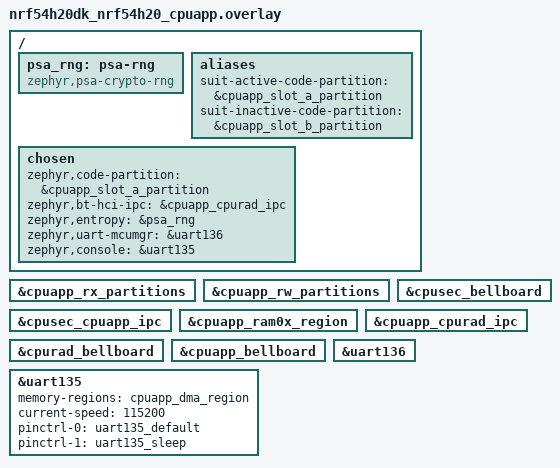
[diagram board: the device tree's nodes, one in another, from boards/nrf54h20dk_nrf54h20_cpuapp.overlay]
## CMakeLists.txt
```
#
# Copyright (c) 2025 Nordic Semiconductor ASA
#
# SPDX-License-Identifier: LicenseRef-Nordic-5-Clause
#

cmake_minimum_required(VERSION 3.13.1)

find_package(Zephyr REQUIRED HINTS $ENV{ZEPHYR_BASE})

project(suit_ab_images)

target_sources(app PRIVATE src/main.c)

# This project uses orginal sdk-zephyr C source code
target_include_directories(app PRIVATE $ENV{ZEPHYR_BASE}/samples/subsys/mgmt/mcumgr/smp_svr/src)
target_sources_ifdef(CONFIG_MCUMGR_TRANSPORT_BT app PRIVATE $ENV{ZEPHYR_BASE}/samples/subsys/mgmt/mcumgr/smp_svr/src/bluetooth.c)
```

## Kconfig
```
#
# Copyright (c) 2025 Nordic Semiconductor ASA
#
# SPDX-License-Identifier: LicenseRef-Nordic-5-Clause
#

config N_BLINKS
	int "Number of fast blinks"
	default 1

config ID_VAR_BOOT_STATUS
	int "Id of Manfiest-controlled variable representing a boot status"
	default 256

config ID_VAR_BOOT_PREFERENCE
	int "Id of Manfiest-controlled variable representing a boot prefrence"
	default 0

config ID_VAR_SET_TO_UPDATE
	int "Id of Manfiest-controlled variable representing image set to be updated"
	default 1

config ID_VAR_CONFIRM_SET_A
	int "Id of Manfiest-controlled variable representing after-update confirmation state for image set A"
	default 2

config ID_VAR_CONFIRM_SET_B
	int "Id of Manfiest-controlled variable representing after-update confirmation state for image set B"
	default 3

source "Kconfig.zephyr"
```

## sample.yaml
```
#
# Copyright (c) 2025 Nordic Semiconductor ASA
#
# SPDX-License-Identifier: LicenseRef-Nordic-5-Clause
#

sample:
  name: SUIT A/B update through SMP sample
  description: Sample application that A/B updates firmware using SUIT and SMP protocol
common:
  platform_allow: nrf54h20dk/nrf54h20/cpuapp
  build_only: true
  sysbuild: true
tests:
  sample.suit.ab:
    extra_args:
    - SB_EXTRA_CONF_FILE="suit_mpi.conf"
    tags:
      - suit
      - bluetooth
      - ci_samples_suit
```

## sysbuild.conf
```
#
# Copyright (c) 2025 Nordic Semiconductor ASA
#
# SPDX-License-Identifier: LicenseRef-Nordic-5-Clause
#

SB_CONFIG_SUIT_ENVELOPE=y
SB_CONFIG_NETCORE_HCI_IPC=y

SB_CONFIG_SUIT_BUILD_AB_UPDATE=y
SB_CONFIG_SUIT_MPI_APP_LOCAL_2=y
SB_CONFIG_SUIT_MPI_RAD_LOCAL_2=y
```

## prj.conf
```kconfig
#
# Copyright (c) 2025 Nordic Semiconductor ASA
#
# SPDX-License-Identifier: LicenseRef-Nordic-5-Clause
#

# Enable DK LED library
CONFIG_DK_LIBRARY=y

# Enable mcumgr
CONFIG_NET_BUF=y
CONFIG_ZCBOR=y
CONFIG_ZCBOR_CANONICAL=y
CONFIG_MCUMGR=y
CONFIG_MCUMGR_SMP_LEGACY_RC_BEHAVIOUR=y
CONFIG_CRC=y

# Enable SUIT services
CONFIG_SUIT=y
CONFIG_SUIT_DFU_CANDIDATE_PROCESSING_FULL=y
CONFIG_MGMT_SUITFU=y
CONFIG_FLASH=y

# Extended SUIT commands over USER group
CONFIG_MGMT_SUITFU_GRP_SUIT=y

# Enable bootloader identification within OS Management group
CONFIG_MCUMGR_GRP_OS=y
CONFIG_MCUMGR_GRP_OS_BOOTLOADER_INFO=y
CONFIG_MCUMGR_MGMT_NOTIFICATION_HOOKS=y
CONFIG_MCUMGR_GRP_OS_BOOTLOADER_INFO_HOOK=y

CONFIG_BT=y
CONFIG_BT_PERIPHERAL=y

# Optimize buffer sizes for transport speed
#CONFIG_MCUMGR_TRANSPORT_NETBUF_SIZE=1040
#CONFIG_UART_MCUMGR_RX_BUF_SIZE=1040
#CONFIG_MCUMGR_TRANSPORT_UART_MTU=1024

# Allow for large Bluetooth data packets.
CONFIG_BT_L2CAP_TX_MTU=498
CONFIG_BT_BUF_ACL_RX_SIZE=502
CONFIG_BT_BUF_ACL_TX_SIZE=502

# Enable the Bluetooth mcumgr transport (unauthenticated).
CONFIG_MCUMGR_TRANSPORT_BT=y
CONFIG_MCUMGR_TRANSPORT_BT_PERM_RW=y
CONFIG_MCUMGR_TRANSPORT_BT_CONN_PARAM_CONTROL=y

# Enable logs over UART
CONFIG_LOG=y
CONFIG_SUIT_LOG_LEVEL_DBG=y

# Enable the mcumgr Packet Reassembly feature over Bluetooth and its configuration dependencies.
# MCUmgr buffer size is optimized to fit one SMP packet divided into five Bluetooth Write Commands,
# transmitted with the maximum possible MTU value: 498 bytes.
CONFIG_MCUMGR_TRANSPORT_BT_REASSEMBLY=y
CONFIG_MCUMGR_TRANSPORT_NETBUF_SIZE=2475
CONFIG_MCUMGR_TRANSPORT_WORKQUEUE_STACK_SIZE=4096

CONFIG_BT_DEVICE_NAME="SUIT AB Sample"
```

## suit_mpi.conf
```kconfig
#
# Copyright (c) 2025 Nordic Semiconductor ASA
#
# SPDX-License-Identifier: LicenseRef-Nordic-5-Clause
#
# ATTENTION! This is the right place to define a configuration for SUIT manifests in end-product
# and practically all config values included in that file shall be adjusted according 
# to end-product needs/requirements.
# see: nrf/doc/nrf/app_dev/device_guides/nrf54h/ug_nrf54h20_suit_dfu.rst
# 
# SB_CONFIG_SUIT_MPI_$(manifest)_VENDOR_NAME: Vendor-specific string *SHALL* be configured for *ALL* listed entries below.
# It may be the same value, i.e. "acme.com", for all entries, replacing existing "nordicsemi.com"
#
# SB_CONFIG_SUIT_MPI_$(manifest)_CLASS_NAME: Unique string prevents an update with firmware dedicated to other product
# Proposed schema: Manifest role + End Product model name.
# It *SHALL* be configured for *ALL* entries below, i.e.
# "nRF54H20_sample_root" replaced with "root_light_bulb_model_x123"
# "nRF54H20_sample_app" replaced with "app_A_light_bulb_model_x123"
# "nRF54H20_sample_app_local_2" replaced with "app_B_light_bulb_model_x123"
# 
# Signature check policy for given manifest, select one of possible options:
# SB_CONFIG_SUIT_MPI_$(manifest)_SIGNATURE_CHECK_DISABLED=y, or
# SB_CONFIG_SUIT_MPI_$(manifest)_SIGNATURE_CHECK_ENABLED_ON_UPDATE=y, or
# SB_CONFIG_SUIT_MPI_$(manifest)_SIGNATURE_CHECK_ENABLED_ON_UPDATE_AND_BOOT=y

SB_CONFIG_SUIT_MPI_ROOT_VENDOR_NAME="nordicsemi.com"
SB_CONFIG_SUIT_MPI_ROOT_CLASS_NAME="nRF54H20_sample_root"
SB_CONFIG_SUIT_MPI_ROOT_DOWNGRADE_PREVENTION=y
SB_CONFIG_SUIT_MPI_ROOT_INDEPENDENT_UPDATE=y
SB_CONFIG_SUIT_MPI_ROOT_SIGNATURE_CHECK_ENABLED_ON_UPDATE_AND_BOOT=y

SB_CONFIG_SUIT_MPI_APP_RECOVERY=y
SB_CONFIG_SUIT_MPI_APP_RECOVERY_VENDOR_NAME="nordicsemi.com"
SB_CONFIG_SUIT_MPI_APP_RECOVERY_CLASS_NAME="nRF54H20_app_recovery"
SB_CONFIG_SUIT_MPI_APP_RECOVERY_DOWNGRADE_PREVENTION=y
SB_CONFIG_SUIT_MPI_APP_RECOVERY_INDEPENDENT_UPDATE=y
SB_CONFIG_SUIT_MPI_APP_RECOVERY_SIGNATURE_CHECK_ENABLED_ON_UPDATE_AND_BOOT=y

SB_CONFIG_SUIT_MPI_APP_LOCAL_1=y
SB_CONFIG_SUIT_MPI_APP_LOCAL_1_VENDOR_NAME="nordicsemi.com"
SB_CONFIG_SUIT_MPI_APP_LOCAL_1_CLASS_NAME="nRF54H20_sample_app"
SB_CONFIG_SUIT_MPI_APP_LOCAL_1_DOWNGRADE_PREVENTION=n
SB_CONFIG_SUIT_MPI_APP_LOCAL_1_INDEPENDENT_UPDATE=n
SB_CONFIG_SUIT_MPI_APP_LOCAL_1_SIGNATURE_CHECK_ENABLED_ON_UPDATE_AND_BOOT=y

SB_CONFIG_SUIT_MPI_APP_LOCAL_2=y
SB_CONFIG_SUIT_MPI_APP_LOCAL_2_VENDOR_NAME="nordicsemi.com"
SB_CONFIG_SUIT_MPI_APP_LOCAL_2_CLASS_NAME="nRF54H20_sample_app_local_2"
SB_CONFIG_SUIT_MPI_APP_LOCAL_2_DOWNGRADE_PREVENTION=n
SB_CONFIG_SUIT_MPI_APP_LOCAL_2_INDEPENDENT_UPDATE=n
SB_CONFIG_SUIT_MPI_APP_LOCAL_2_SIGNATURE_CHECK_ENABLED_ON_UPDATE_AND_BOOT=y

SB_CONFIG_SUIT_MPI_APP_LOCAL_3=n

SB_CONFIG_SUIT_MPI_RAD_RECOVERY=n

SB_CONFIG_SUIT_MPI_RAD_LOCAL_1=y
SB_CONFIG_SUIT_MPI_RAD_LOCAL_1_VENDOR_NAME="nordicsemi.com"
SB_CONFIG_SUIT_MPI_RAD_LOCAL_1_CLASS_NAME="nRF54H20_sample_rad"
SB_CONFIG_SUIT_MPI_RAD_LOCAL_1_DOWNGRADE_PREVENTION=n
SB_CONFIG_SUIT_MPI_RAD_LOCAL_1_INDEPENDENT_UPDATE=n
SB_CONFIG_SUIT_MPI_RAD_LOCAL_1_SIGNATURE_CHECK_ENABLED_ON_UPDATE_AND_BOOT=y

SB_CONFIG_SUIT_MPI_RAD_LOCAL_2=y
SB_CONFIG_SUIT_MPI_RAD_LOCAL_2_VENDOR_NAME="nordicsemi.com"
SB_CONFIG_SUIT_MPI_RAD_LOCAL_2_CLASS_NAME="nRF54H20_sample_rad_local_2"
SB_CONFIG_SUIT_MPI_RAD_LOCAL_2_DOWNGRADE_PREVENTION=n
SB_CONFIG_SUIT_MPI_RAD_LOCAL_2_INDEPENDENT_UPDATE=n
SB_CONFIG_SUIT_MPI_RAD_LOCAL_2_SIGNATURE_CHECK_ENABLED_ON_UPDATE_AND_BOOT=y
```

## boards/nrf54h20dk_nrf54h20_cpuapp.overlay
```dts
/*
 * Copyright (c) 2025 Nordic Semiconductor ASA
 *
 * SPDX-License-Identifier: LicenseRef-Nordic-5-Clause
 */

 #include "../sysbuild/nrf54h20dk_nrf54h20_memory_map.dtsi"

/* Enable partitions, belonging to the application domain. */
&cpuapp_rx_partitions {
	status = "okay";
};

&cpuapp_rw_partitions {
	status = "okay";
};

/* Enable IPC: Application <-> Secure */
&cpusec_cpuapp_ipc {
	status = "okay";
};

&cpuapp_ram0x_region {
	status = "okay";
};

&cpusec_bellboard {
	status = "okay";
};

/* Enable IPC: Application <-> Radio */
&cpuapp_cpurad_ipc {
	status = "okay";
};

&cpurad_bellboard {
	status = "okay";
};

&cpuapp_bellboard {
	status = "okay";
};

/* Disable HW flow control on the UART 0 */
&uart136 {
	/delete-property/ hw-flow-control;
};

/ {
	psa_rng: psa-rng {
		compatible = "zephyr,psa-crypto-rng";
		status = "okay";
	};

	aliases {
		suit-active-code-partition = &cpuapp_slot_a_partition;
		suit-inactive-code-partition = &cpuapp_slot_b_partition;
	};

	chosen {
		zephyr,code-partition = &cpuapp_slot_a_partition;
		zephyr,bt-hci-ipc = &cpuapp_cpurad_ipc;
		zephyr,entropy = &psa_rng;
		zephyr,uart-mcumgr = &uart136;
	};
};

/* UART 1 is configured for App Core console output. In order to use it for other
 * purpose, i.e. to output logs form the Radio core, remove section below.
 */
&uart135 {
	status = "okay";
	memory-regions = <&cpuapp_dma_region>;
	current-speed = <115200>;
	pinctrl-0 = <&uart135_default>;
	pinctrl-1 = <&uart135_sleep>;
	pinctrl-names = "default", "sleep";

	/delete-property/ hw-flow-control;
};

/ {
	chosen {
		zephyr,console = &uart135;
	};
};
```

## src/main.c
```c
/*
 * Copyright (c) 2025 Nordic Semiconductor ASA
 *
 * SPDX-License-Identifier: LicenseRef-Nordic-5-Clause
 */

#include <zephyr/kernel.h>
#include <dk_buttons_and_leds.h>
#ifdef CONFIG_MGMT_SUITFU
#include <suitfu_mgmt.h>
#endif /* CONFIG_MGMT_SUITFU */
#include <zephyr/storage/flash_map.h>
#include "common.h"

#ifdef CONFIG_SSF_SUIT_SERVICE_ENABLED
#include <sdfw/sdfw_services/suit_service.h>
#endif /* CONFIG_SSF_SUIT_SERVICE_ENABLED */

#define DFU_PARTITION_OFFSET  FIXED_PARTITION_OFFSET(dfu_partition)
#define DFU_PARTITION_SIZE    FIXED_PARTITION_SIZE(dfu_partition)
#define DFU_PARTITION_ADDRESS suit_plat_mem_nvm_ptr_get(DFU_PARTITION_OFFSET)

int main(void)
{
	int ret = dk_leds_init();

	if (ret) {
		printk("Cannot init LEDs (err: %d)\r\n", ret);
	}

	printk("Hello world from %s blinks: %d, BUILD: %s %s\r\n", CONFIG_BOARD, CONFIG_N_BLINKS,
	       __DATE__, __TIME__);

	if (IS_ENABLED(CONFIG_MCUMGR_TRANSPORT_BT)) {
		start_smp_bluetooth_adverts();
	}

	while (1) {
		for (int i = 0; i < CONFIG_N_BLINKS; i++) {
			dk_set_led_on(DK_LED1);
			k_msleep(250);
			dk_set_led_off(DK_LED1);
			k_msleep(250);
		}

		k_msleep(5000);
	}

	return 0;
}
```

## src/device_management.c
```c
/*
 * Copyright (c) 2025 Nordic Semiconductor ASA
 *
 * SPDX-License-Identifier: LicenseRef-Nordic-5-Clause
 */

#include <zephyr/kernel.h>
#include <suit_manifest_variables.h>
#include <device_management.h>
#include <zephyr/logging/log.h>
#include <sdfw/sdfw_services/suit_service.h>
#include <zephyr/bluetooth/bluetooth.h>

LOG_MODULE_DECLARE(AB, CONFIG_SUIT_LOG_LEVEL);

#define NOT_CONFIRMED 2
#define CONFIRMED     3

#define BOOT_PREFERENCE_A 1
#define BOOT_PREFERENCE_B 2

/** @brief Radio firmware self test
 *
 * @details
 * End-device specific self test should be implemented here.
 */
static bool radio_domain_healthy(void)
{
	return bt_is_ready();
}

/** @brief Application firmware self test
 *
 * @details
 * End-device specific self test should be implemented here. Enabling
 * CONFIG_EMULATE_APP_HEALTH_CHECK_FAILURE allows to emulate a faulty
 * firmware, unable to confirm its health, and ultimately to test
 * a rollback to previous firmware after the update.
 */
static bool app_domain_healthy(void)
{
	if (IS_ENABLED(CONFIG_EMULATE_APP_HEALTH_CHECK_FAILURE)) {
		return false;
	}

	return true;
}

bool device_is_in_recovery_mode(void)
{
	static suit_boot_mode_t mode = SUIT_BOOT_MODE_UNKNOWN;
	suit_plat_err_t err = SUIT_PLAT_SUCCESS;

	if (mode == SUIT_BOOT_MODE_UNKNOWN) {
		err  = suit_boot_mode_read(&mode);
		if (err != SUIT_PLAT_SUCCESS) {
			LOG_ERR("Cannot get the boot mode");
			mode = SUIT_BOOT_MODE_FAIL_STARTUP;
		}
	}

	return (mode == SUIT_BOOT_MODE_POST_INVOKE_RECOVERY);
}

uint32_t device_boot_status_get(void)
{
	suit_plat_err_t err = SUIT_PLAT_SUCCESS;
	static uint32_t mfst_var_boot_status = 0;

	if (mfst_var_boot_status == 0) {
		err = suit_mfst_var_get(CONFIG_ID_VAR_BOOT_STATUS, &mfst_var_boot_status);
		if (err != SUIT_PLAT_SUCCESS) {
			LOG_ERR("Cannot get a device boot status");
			mfst_var_boot_status = BOOT_STATUS_CANT_BOOT;
		}
	}


	return mfst_var_boot_status;
}

void device_healthcheck(void)
{
	suit_plat_err_t err = SUIT_PLAT_SUCCESS;
	char *img_set = NULL;
	uint32_t mfst_var_boot_status = BOOT_STATUS_CANT_BOOT;
	uint32_t mfst_var_confirm_status = CONFIRMED;
	uint32_t id_var_confirm_set = CONFIG_ID_VAR_CONFIRM_SET_A;

	mfst_var_boot_status = device_boot_status_get();

	if (mfst_var_boot_status == BOOT_STATUS_CANT_BOOT) {
		return;
	}

	/* Confirming only in non-degraded boot states
	 */
	if (DT_SAME_NODE(DT_ALIAS(suit_active_code_partition),
			 DT_NODELABEL(cpuapp_slot_a_partition))) {
		if (mfst_var_boot_status != BOOT_STATUS_A) {
			return;
		}
		img_set = "A";
	} else {
		if (mfst_var_boot_status != BOOT_STATUS_B) {
			return;
		}

		img_set = "B";
		id_var_confirm_set = CONFIG_ID_VAR_CONFIRM_SET_B;
	}

	err = suit_mfst_var_get(id_var_confirm_set, &mfst_var_confirm_status);
	if (err != SUIT_PLAT_SUCCESS) {
		LOG_ERR("Cannot get a confirm status");
		return;
	}

	if (mfst_var_confirm_status != CONFIRMED) {
		LOG_INF("Image set %s not confirmed yet, testing...", img_set);

		bool healthy = true;

		if (!radio_domain_healthy()) {
			LOG_ERR("Radio domain is NOT healthy");
			healthy = false;
		}

		if (!app_domain_healthy()) {
			LOG_ERR("App domain is NOT healthy");
			healthy = false;
		}

		if (!healthy) {
			LOG_ERR("Reboot the device to try to boot from previous firmware");
			return;
		}

		LOG_INF("Confirming...");
		err = suit_mfst_var_set(id_var_confirm_set, CONFIRMED);
		if (err == SUIT_PLAT_SUCCESS) {
			LOG_INF("Confirmed\n");
		}
	}
}

void toggle_preferred_boot_set(void)
{
	suit_plat_err_t err = SUIT_PLAT_SUCCESS;
	uint32_t mfst_var_boot_preference = 0;

	err = suit_mfst_var_get(CONFIG_ID_VAR_BOOT_PREFERENCE, &mfst_var_boot_preference);
	if (err != SUIT_PLAT_SUCCESS) {
		LOG_ERR("Cannot get current boot preference");
		return;
	}

	if (mfst_var_boot_preference == BOOT_PREFERENCE_B) {
		LOG_INF("Changing a boot preference (b -> A)");
		mfst_var_boot_preference = BOOT_PREFERENCE_A;
	} else {
		LOG_INF("Changing a boot preference (a -> B)");
		mfst_var_boot_preference = BOOT_PREFERENCE_B;
	}

	err = suit_mfst_var_set(CONFIG_ID_VAR_BOOT_PREFERENCE, mfst_var_boot_preference);
	if (err == SUIT_PLAT_SUCCESS) {
		LOG_INF("restart the device to enforce\n");
	} else {
		LOG_ERR("Cannot set a boot preference");
	}
}

void device_boot_state_report(void)
{
	suit_plat_err_t err = SUIT_PLAT_SUCCESS;
	uint32_t mfst_var_boot_preference = 0;
	uint32_t mfst_var_boot_status = 0;
	uint32_t mfst_var_confirm_set_a = 0;
	uint32_t mfst_var_confirm_set_b = 0;

	if (device_is_in_recovery_mode()) {
		printk("Boot in RECOVERY mode, probably the root manifest is damaged!\n");
	}

	err = suit_mfst_var_get(CONFIG_ID_VAR_BOOT_PREFERENCE, &mfst_var_boot_preference);
	if (err == SUIT_PLAT_SUCCESS) {
		if (mfst_var_boot_preference == BOOT_PREFERENCE_B) {
			printk("Boot preference: set B\n");
		} else {
			printk("Boot preference: set A\n");
		}
	}

	mfst_var_boot_status = device_boot_status_get();

	if (mfst_var_boot_status == BOOT_STATUS_A) {
		printk("Boot status: image set A active\n");
	} else if (mfst_var_boot_status == BOOT_STATUS_B) {
		printk("Boot status: image set B active\n");
	} else if (mfst_var_boot_status == BOOT_STATUS_A_DEGRADED) {
		printk("Boot status: image set A active, degraded mode\n");
	} else if (mfst_var_boot_status == BOOT_STATUS_B_DEGRADED) {
		printk("Boot status: app image B active, degraded mode\n");
	} else if (mfst_var_boot_status == BOOT_STATUS_A_NO_RADIO) {
		printk("Boot status: app image A active, no radio, degraded mode\n");
	} else if (mfst_var_boot_status == BOOT_STATUS_B_NO_RADIO) {
		printk("Boot status: app image B active, no radio, degraded mode\n");
	} else {
		printk("Boot status: unrecognized\n");
	}

	err = suit_mfst_var_get(CONFIG_ID_VAR_CONFIRM_SET_A, &mfst_var_confirm_set_a);
	if (err == SUIT_PLAT_SUCCESS) {
		if (mfst_var_confirm_set_a == NOT_CONFIRMED) {
			printk("Confirm status set A: not confirmed\n");
		} else if (mfst_var_confirm_set_a == CONFIRMED) {
			printk("Confirm status set A: confirmed\n");
		} else {
			printk("Confirm status set A: just installed\n");
		}
	}

	err = suit_mfst_var_get(CONFIG_ID_VAR_CONFIRM_SET_B, &mfst_var_confirm_set_b);
	if (err == SUIT_PLAT_SUCCESS) {
		if (mfst_var_confirm_set_b == NOT_CONFIRMED) {
			printk("Confirm status set B: not confirmed\n");
		} else if (mfst_var_confirm_set_b == CONFIRMED) {
			printk("Confirm status set B: confirmed\n");
		} else {
			printk("Confirm status set B: just installed\n");
		}
	}
}
```

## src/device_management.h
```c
/*
 * Copyright (c) 2025 Nordic Semiconductor ASA
 *
 * SPDX-License-Identifier: LicenseRef-Nordic-5-Clause
 */

#ifndef DEVICE_MANAGEMANT_H__
#define DEVICE_MANAGEMANT_H__

#ifdef __cplusplus
extern "C" {
#endif

/** @brief Performs a self-tests and confirms
 * successful firmware update, if needed
 */
void device_healthcheck(void);

/** @brief Toggles preferred boot set
 */
void toggle_preferred_boot_set();

/** @brief Displays information about state of image sets,
 * boot preference and a boot status
 */
void device_boot_state_report(void);

#endif /* DEVICE_MANAGEMANT_H__ */
```
